AUTOSAR XML (schema 00050)
package /MICROSAR/Dem_swc/DataTypes
  23 x impl type:
    Dem_EventIdType: range raw 1..65535, implementation-data-type=uint16
    Dem_RatioIdType: range raw 1..65535, implementation-data-type=uint16
    Dem_DTCStatusMaskType: range raw 0..255, implementation-data-type=uint8
    Dem_OperationCycleIdType: range raw 0..255, implementation-data-type=uint8
    Dem_DTCGroupType: range raw 0..16777215, implementation-data-type=uint32
    Dem_MaxDataValueType: category=ARRAY, sw-calibration-access=READ-ONLY
      element Dem_MaxDataValueTypeElement: array-size=1, array-size-semantics=FIXED-SIZE, implementation-data-type=uint8
    Dem_EventStatusType:
      compu {0=DEM_EVENT_STATUS_PASSED, 1=DEM_EVENT_STATUS_FAILED, 2=DEM_EVENT_STATUS_PREPASSED, 3=DEM_EVENT_STATUS_PREFAILED, 4=DEM_EVENT_STATUS_FDC_THRESHOLD_REACHED, 5=DEM_EVENT_STATUS_PASSED_CONDITIONS_NOT_FULFILLED, 6=DEM_EVENT_STATUS_FAILED_CONDITIONS_NOT_FULFILLED, 7=DEM_EVENT_STATUS_PREPASSED_CONDITIONS_NOT_FULFILLED, 8=DEM_EVENT_STATUS_PREFAILED_CONDITIONS_NOT_FULFILLED}
      range raw 0..255
      implementation-data-type=uint8
    Dem_InitMonitorReasonType: compu {1=DEM_INIT_MONITOR_CLEAR, 2=DEM_INIT_MONITOR_RESTART, 3=DEM_INIT_MONITOR_REENABLED, 4=DEM_INIT_MONITOR_STORAGE_REENABLED}, range raw 1..4, implementation-data-type=uint8
    Dem_DTCOriginType: compu {1=DEM_DTC_ORIGIN_PRIMARY_MEMORY, 2=DEM_DTC_ORIGIN_MIRROR_MEMORY, 3=DEM_DTC_ORIGIN_PERMANENT_MEMORY, 4=DEM_DTC_ORIGIN_OBD_RELEVANT_MEMORY, 256=DEM_DTC_ORIGIN_SECONDARY_MEMORY}, range raw 1..511, implementation-data-type=uint16
    Dem_DTCFormatType: compu {0=DEM_DTC_FORMAT_OBD, 1=DEM_DTC_FORMAT_UDS, 2=DEM_DTC_FORMAT_J1939}, range raw 0..2, implementation-data-type=uint8
    Dem_OperationCycleStateType: compu {0=DEM_CYCLE_STATE_START, 1=DEM_CYCLE_STATE_END}, range raw 0..1, implementation-data-type=uint8
    Dem_IndicatorStatusType: compu {0=DEM_INDICATOR_OFF, 1=DEM_INDICATOR_CONTINUOUS, 2=DEM_INDICATOR_BLINKING, 3=DEM_INDICATOR_BLINK_CONT, 4=DEM_INDICATOR_SLOW_FLASH, 5=DEM_INDICATOR_FAST_FLASH, 6=DEM_INDICATOR_ON_DEMAND, 7=DEM_INDICATOR_SHORT}, range raw 0..7, implementation-data-type=uint8
    Dem_DTCKindType: compu {1=DEM_DTC_KIND_ALL_DTCS, 2=DEM_DTC_KIND_EMISSION_REL_DTCS}, range raw 0..255, implementation-data-type=uint8
    Dem_IumprDenomCondIdType: compu {1=DEM_IUMPR_GENERAL_DENOMINATOR, 2=DEM_IUMPR_DEN_COND_COLDSTART, 3=DEM_IUMPR_DEN_COND_EVAP, 4=DEM_IUMPR_DEN_COND_500MI, 5=DEM_IUMPR_GENERAL_INDIVIDUAL_DENOMINATOR, 6=DEM_IUMPR_GENERAL_OBDCOND, 7=DEM_IUMPR_DEN_COND_INDEPENDENT}, range raw 0..255, implementation-data-type=uint8
    Dem_IumprDenomCondStatusType: compu {0=DEM_IUMPR_DEN_STATUS_NOT_REACHED, 1=DEM_IUMPR_DEN_STATUS_REACHED, 2=DEM_IUMPR_DEN_STATUS_INHIBITED}, range raw 0..255, implementation-data-type=uint8
    Dem_DebounceResetStatusType: compu {0=DEM_DEBOUNCE_STATUS_FREEZE, 1=DEM_DEBOUNCE_STATUS_RESET}, range raw 0..255, implementation-data-type=uint8
    Dem_IumprReadinessGroupType:
      compu {0=DEM_IUMPR_BOOSTPRS, 1=DEM_IUMPR_CAT1, 2=DEM_IUMPR_CAT2, 3=DEM_IUMPR_EGR, 4=DEM_IUMPR_EGSENSOR, 5=DEM_IUMPR_EVAP, 6=DEM_IUMPR_NMHCCAT, 7=DEM_IUMPR_NOXADSORB, 8=DEM_IUMPR_NOXCAT, 9=DEM_IUMPR_OXS1, 10=DEM_IUMPR_OXS2, 11=DEM_IUMPR_PMFILTER, 12=DEM_IUMPR_PRIVATE, 13=DEM_IUMPR_SAIR, 14=DEM_IUMPR_SECOXS1, 15=DEM_IUMPR_SECOXS2, 16=DEM_IUMPR_FLSYS, 17=DEM_IUMPR_AFRI1, 18=DEM_IUMPR_AFRI2, 19=DEM_IUMPR_PF1, 20=DEM_IUMPR_PF2, 255=DEM_IUMPR_ALLGROUPS}
      range raw 0..255
      implementation-data-type=uint8
    Dem_DTRControlType: compu {0=DEM_DTR_CTL_NORMAL, 1=DEM_DTR_CTL_NO_MAX, 2=DEM_DTR_CTL_NO_MIN, 3=DEM_DTR_CTL_RESET, 4=DEM_DTR_CTL_INVISIBLE}, range raw 0..255, implementation-data-type=uint8
    Dem_DebouncingStateType:
      compu {mask 1: 1=DEM_TEMPORARILY_DEFECTIVE (Bit 0: Temporarily Defective (corresponds to 0 < FDC < 127)), mask 2: 2=DEM_FINALLY_DEFECTIVE (Bit 1: Finally Defective (corresponds to FDC = 127)), mask 4: 4=DEM_TEMPORARILY_HEALED (Bit 2: Temporarily healed (corresponds to -128 < FDC < 0)), mask 8: 8=DEM_TEST_COMPLETE (Bit 3: Test complete (corresponds to FDC = -128 or FDC = 127)), mask 16: 16=DEM_DTR_UPDATE (Bit 4: DTR Update (= Test complete && Debouncing complete && enable conditions / storage conditions fulfilled))}
      range raw 0..255
      implementation-data-type=uint8
    Dem_DTCSeverityType:
      compu {mask 255: 0=DEM_SEVERITY_NO_SEVERITY (DTC_NO_SEVERITY) (No severity information available), mask 31: 1=DEM_SEVERITY_WWHOBD_CLASS_NO_CLASS (DTC_CLASS) (No class information), mask 31: 2=DEM_SEVERITY_WWHOBD_CLASS_A (DTC_CLASS) (WWH-OBD Class A), mask 31: 4=DEM_SEVERITY_WWHOBD_CLASS_B1 (DTC_CLASS) (WWH-OBD Class B1), mask 31: 8=DEM_SEVERITY_WWHOBD_CLASS_B2 (DTC_CLASS) (WWH-OBD Class B2), mask 31: 16=DEM_SEVERITY_WWHOBD_CLASS_C (DTC_CLASS) (WWH-OBD Class C), mask 224: 32=DEM_SEVERITY_MAINTENANCE_ONLY (DTC_SEVERITY) (Maintenance required), mask 224: 64=DEM_SEVERITY_CHECK_AT_NEXT_HALT (DTC_SEVERITY) (Check at next halt), mask 224: 128=DEM_SEVERITY_CHECK_IMMEDIATELY (DTC_SEVERITY) (Check immediately)}
      range raw 0..255
      implementation-data-type=uint8
    Dem_UdsStatusByteType:
      compu {mask 1: 1=DEM_UDS_STATUS_TF (bit 0: TestFailed), mask 2: 2=DEM_UDS_STATUS_TFTOC (bit 1: TestFailedThisOperationCycle), mask 4: 4=DEM_UDS_STATUS_PDTC (bit 2: PendingDTC), mask 8: 8=DEM_UDS_STATUS_CDTC (bit 3: ConfirmedDTC), mask 16: 16=DEM_UDS_STATUS_TNCSLC (bit 4: TestNotCompletedSinceLastClear), mask 32: 32=DEM_UDS_STATUS_TFSLC (bit 5: TestFailedSinceLastClear), mask 64: 64=DEM_UDS_STATUS_TNCTOC (bit 6: TestNotCompletedThisOperationCycle), mask 128: 128=DEM_UDS_STATUS_WIR (bit 7: WarningIndicatorRequested)}
      range raw 0..255
      implementation-data-type=uint8
    Dem_MonitorStatusType: compu {mask 1: 1=DEM_MONITOR_STATUS_TF (bit 0: TestFailed), mask 2: 2=DEM_MONITOR_STATUS_TNCTOC (bit 1: TestNotCompletedThisOperationCycle)}, range raw 0..255, implementation-data-type=uint8
    DataPrimitiveType_uint8: implementation-data-type=uint8
package /MICROSAR/Dem_swc/Interfaces
  9 x client server interface, all with is-service=true, service-kind=DIAGNOSTIC-EVENT-MANAGER:
    DemServices
      operation GetPostRunRequested: possible-error=DemServices/E_NOT_OK
        arg IsRequested: type=boolean, direction=OUT
      operation GetDTCStatusAvailabilityMask: possible-error=DemServices/E_NOT_OK
        arg ClientId: type=uint8, direction=IN
        arg DTCStatusMask: type=uint8, direction=OUT
      error E_NOT_OK: error-code=1
    ClearDTC
      operation ClearDTC: possible-error=[ClearDTC/E_NOT_OK, DEM_CLEAR_FAILED, DEM_PENDING, DEM_CLEAR_BUSY, DEM_CLEAR_MEMORY_ERROR, DEM_WRONG_DTC, DEM_WRONG_DTCORIGIN]
      operation SelectDTC: possible-error=[ClearDTC/E_OK, ClearDTC/E_NOT_OK]
        arg DTC: type=uint32, direction=IN
        arg DTCFormat: type=Dem_DTCFormatType, direction=IN
        arg DTCOrigin: type=Dem_DTCOriginType, direction=IN
      8 x error:
        E_OK: error-code=0
        E_NOT_OK: error-code=1
        DEM_CLEAR_FAILED: error-code=7
        DEM_PENDING: error-code=4
        DEM_CLEAR_BUSY: error-code=5
        DEM_CLEAR_MEMORY_ERROR: error-code=6
        DEM_WRONG_DTC: error-code=8
        DEM_WRONG_DTCORIGIN: error-code=9
    EvMemOverflowIndication
      operation GetEventMemoryOverflow: possible-error=EvMemOverflowIndication/E_NOT_OK
        arg OverflowIndication: type=boolean, direction=OUT
      operation GetNumberOfEventMemoryEntries: possible-error=EvMemOverflowIndication/E_NOT_OK
        arg NumberOfEventMemoryEntries: type=uint8, direction=OUT
      error E_NOT_OK: error-code=1
    GeneralDiagnosticInfo
      11 x operation:
        GetEventUdsStatus: possible-error=GeneralDiagnosticInfo/E_NOT_OK
          arg EventId: type=Dem_EventIdType, direction=IN
          arg UDSStatusByte: type=Dem_UdsStatusByteType, direction=OUT
        GetEventStatus: possible-error=GeneralDiagnosticInfo/E_NOT_OK
          arg EventId: type=Dem_EventIdType, direction=IN
          arg UDSStatusByte: type=Dem_UdsStatusByteType, direction=OUT
        GetEventFailed: possible-error=GeneralDiagnosticInfo/E_NOT_OK
          arg EventId: type=Dem_EventIdType, direction=IN
          arg EventFailed: type=boolean, direction=OUT
        GetEventTested: possible-error=GeneralDiagnosticInfo/E_NOT_OK
          arg EventId: type=Dem_EventIdType, direction=IN
          arg EventTested: type=boolean, direction=OUT
        GetDTCOfEvent: possible-error=[GeneralDiagnosticInfo/E_NOT_OK, GeneralDiagnosticInfo/DEM_E_NO_DTC_AVAILABLE]
          arg EventId: type=Dem_EventIdType, direction=IN
          arg DTCFormat: type=Dem_DTCFormatType, direction=IN
          arg DTCOfEvent: type=uint32, direction=OUT
        GetFaultDetectionCounter: possible-error=[GeneralDiagnosticInfo/E_NOT_OK, GeneralDiagnosticInfo/DEM_E_NO_FDC_AVAILABLE]
          arg EventId: type=Dem_EventIdType, direction=IN
          arg FaultDetectionCounter: type=sint8, direction=OUT
        GetEventFreezeFrameDataEx: possible-error=[GeneralDiagnosticInfo/E_NOT_OK, GeneralDiagnosticInfo/DEM_BUFFER_TOO_SMALL, GeneralDiagnosticInfo/DEM_NO_SUCH_ELEMENT]
          5 x arg:
            EventId: type=Dem_EventIdType, direction=IN
            RecordNumber: type=uint8, direction=IN
            DataId: type=uint16, direction=IN
            DestBuffer: type=Dem_MaxDataValueType, direction=OUT
            BufSize: type=uint16, direction=INOUT
        GetEventExtendedDataRecordEx: possible-error=[GeneralDiagnosticInfo/E_NOT_OK, GeneralDiagnosticInfo/DEM_BUFFER_TOO_SMALL, GeneralDiagnosticInfo/DEM_NO_SUCH_ELEMENT]
          4 x arg:
            EventId: type=Dem_EventIdType, direction=IN
            RecordNumber: type=uint8, direction=IN
            DestBuffer: type=Dem_MaxDataValueType, direction=OUT
            BufSize: type=uint16, direction=INOUT
        GetEventEnableCondition: possible-error=GeneralDiagnosticInfo/E_NOT_OK
          arg EventId: type=Dem_EventIdType, direction=IN
          arg ConditionFullfilled: type=boolean, direction=OUT
        GetDebouncingOfEvent: possible-error=GeneralDiagnosticInfo/E_NOT_OK
          arg EventId: type=Dem_EventIdType, direction=IN
          arg DebouncingState: type=Dem_DebouncingStateType, direction=OUT
        GetMonitorStatus: possible-error=GeneralDiagnosticInfo/E_NOT_OK
          arg EventId: type=Dem_EventIdType, direction=IN
          arg MonitorStatus: type=Dem_MonitorStatusType, direction=OUT
      5 x error:
        E_NOT_OK: error-code=1
        DEM_E_NO_DTC_AVAILABLE: error-code=10
        DEM_E_NO_FDC_AVAILABLE: error-code=14
        DEM_BUFFER_TOO_SMALL: error-code=21
        DEM_NO_SUCH_ELEMENT: error-code=48
    OperationCycle
      operation GetOperationCycleState: possible-error=[OperationCycle/E_OK, OperationCycle/E_NOT_OK]
        arg CycleState: type=Dem_OperationCycleStateType, direction=OUT
      operation SetOperationCycleState: possible-error=[OperationCycle/E_OK, OperationCycle/E_NOT_OK]
        arg CycleState: type=Dem_OperationCycleStateType, direction=IN
      error E_OK: error-code=0
      error E_NOT_OK: error-code=1
    CSDataServices_DID_0x2_Current
      operation ReadData: possible-error=CSDataServices_DID_0x2_Current/E_NOT_OK
        arg Data: type=DataPrimitiveType_uint8, direction=OUT
      error E_NOT_OK: error-code=1
    DiagnosticInfo
      11 x operation:
        GetEventUdsStatus: possible-error=DiagnosticInfo/E_NOT_OK
          arg UDSStatusByte: type=Dem_UdsStatusByteType, direction=OUT
        GetEventStatus: possible-error=DiagnosticInfo/E_NOT_OK
          arg UDSStatusByte: type=Dem_UdsStatusByteType, direction=OUT
        GetEventFailed: possible-error=DiagnosticInfo/E_NOT_OK
          arg EventFailed: type=boolean, direction=OUT
        GetEventTested: possible-error=DiagnosticInfo/E_NOT_OK
          arg EventTested: type=boolean, direction=OUT
        GetDTCOfEvent: possible-error=[DiagnosticInfo/E_NOT_OK, DiagnosticInfo/DEM_E_NO_DTC_AVAILABLE]
          arg DTCFormat: type=Dem_DTCFormatType, direction=IN
          arg DTCOfEvent: type=uint32, direction=OUT
        GetFaultDetectionCounter: possible-error=[DiagnosticInfo/E_NOT_OK, DiagnosticInfo/DEM_E_NO_FDC_AVAILABLE]
          arg FaultDetectionCounter: type=sint8, direction=OUT
        GetEventFreezeFrameDataEx: possible-error=[DiagnosticInfo/E_NOT_OK, DiagnosticInfo/DEM_BUFFER_TOO_SMALL, DiagnosticInfo/DEM_NO_SUCH_ELEMENT]
          4 x arg:
            RecordNumber: type=uint8, direction=IN
            DataId: type=uint16, direction=IN
            DestBuffer: type=Dem_MaxDataValueType, direction=OUT
            BufSize: type=uint16, direction=INOUT
        GetEventExtendedDataRecordEx: possible-error=[DiagnosticInfo/E_NOT_OK, DiagnosticInfo/DEM_BUFFER_TOO_SMALL, DiagnosticInfo/DEM_NO_SUCH_ELEMENT]
          arg RecordNumber: type=uint8, direction=IN
          arg DestBuffer: type=Dem_MaxDataValueType, direction=OUT
          arg BufSize: type=uint16, direction=INOUT
        GetEventEnableCondition: possible-error=DiagnosticInfo/E_NOT_OK
          arg ConditionFullfilled: type=boolean, direction=OUT
        GetDebouncingOfEvent: possible-error=DiagnosticInfo/E_NOT_OK
          arg DebouncingState: type=Dem_DebouncingStateType, direction=OUT
        GetMonitorStatus: possible-error=DiagnosticInfo/E_NOT_OK
          arg MonitorStatus: type=Dem_MonitorStatusType, direction=OUT
      5 x error:
        E_NOT_OK: error-code=1
        DEM_E_NO_DTC_AVAILABLE: error-code=10
        DEM_E_NO_FDC_AVAILABLE: error-code=14
        DEM_BUFFER_TOO_SMALL: error-code=21
        DEM_NO_SUCH_ELEMENT: error-code=48
    DiagnosticMonitor
      11 x operation:
        SetEventStatus: possible-error=DiagnosticMonitor/E_NOT_OK
          arg EventStatus: type=Dem_EventStatusType, direction=IN
        ResetEventStatus: possible-error=DiagnosticMonitor/E_NOT_OK
        ResetEventDebounceStatus: possible-error=DiagnosticMonitor/E_NOT_OK
          arg DebounceResetStatus: type=Dem_DebounceResetStatusType, direction=IN
        GetEventUdsStatus: possible-error=DiagnosticMonitor/E_NOT_OK
          arg UDSStatusByte: type=Dem_UdsStatusByteType, direction=OUT
        GetEventStatus: possible-error=DiagnosticMonitor/E_NOT_OK
          arg UDSStatusByte: type=Dem_UdsStatusByteType, direction=OUT
        GetEventFailed: possible-error=DiagnosticMonitor/E_NOT_OK
          arg EventFailed: type=boolean, direction=OUT
        GetEventTested: possible-error=DiagnosticMonitor/E_NOT_OK
          arg EventTested: type=boolean, direction=OUT
        GetDTCOfEvent: possible-error=[DiagnosticMonitor/E_NOT_OK, DiagnosticMonitor/DEM_E_NO_DTC_AVAILABLE]
          arg DTCFormat: type=Dem_DTCFormatType, direction=IN
          arg DTCOfEvent: type=uint32, direction=OUT
        GetFaultDetectionCounter: possible-error=[DiagnosticMonitor/E_NOT_OK, DiagnosticMonitor/DEM_E_NO_FDC_AVAILABLE]
          arg FaultDetectionCounter: type=sint8, direction=OUT
        GetEventFreezeFrameDataEx: possible-error=[DiagnosticMonitor/E_NOT_OK, DiagnosticMonitor/DEM_BUFFER_TOO_SMALL, DiagnosticMonitor/DEM_NO_SUCH_ELEMENT]
          4 x arg:
            RecordNumber: type=uint8, direction=IN
            DataId: type=uint16, direction=IN
            DestBuffer: type=Dem_MaxDataValueType, direction=OUT
            BufSize: type=uint16, direction=INOUT
        GetEventExtendedDataRecordEx: possible-error=[DiagnosticMonitor/E_NOT_OK, DiagnosticMonitor/DEM_BUFFER_TOO_SMALL, DiagnosticMonitor/DEM_NO_SUCH_ELEMENT]
          arg RecordNumber: type=uint8, direction=IN
          arg DestBuffer: type=Dem_MaxDataValueType, direction=OUT
          arg BufSize: type=uint16, direction=INOUT
      5 x error:
        E_NOT_OK: error-code=1
        DEM_E_NO_DTC_AVAILABLE: error-code=10
        DEM_E_NO_FDC_AVAILABLE: error-code=14
        DEM_BUFFER_TOO_SMALL: error-code=21
        DEM_NO_SUCH_ELEMENT: error-code=48
    CallbackGetFaultDetectCounter
      operation GetFaultDetectionCounter: possible-error=CallbackGetFaultDetectCounter/E_NOT_OK
        arg FaultDetectionCounter: type=sint8, direction=OUT
      error E_NOT_OK: error-code=1
package /MICROSAR/Dem_swc/ComponentTypes
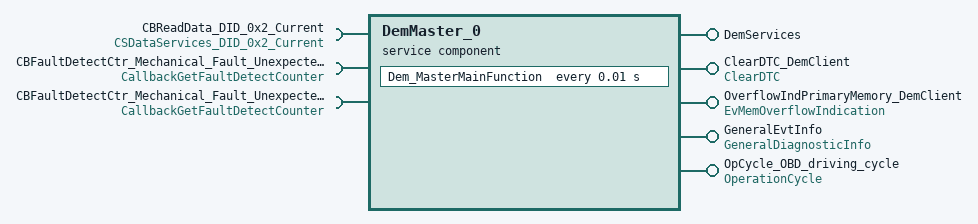
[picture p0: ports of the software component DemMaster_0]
  service sw component type DemMaster_0: category=SERVICE_COMPONENT
    5 x provide port:
      DemServices: provided-interface=DemServices
      ClearDTC_DemClient: provided-interface=ClearDTC
      OverflowIndPrimaryMemory_DemClient: provided-interface=EvMemOverflowIndication
      GeneralEvtInfo: provided-interface=GeneralDiagnosticInfo
      OpCycle_OBD_driving_cycle: provided-interface=OperationCycle
    require port CBReadData_DID_0x2_Current: required-interface=CSDataServices_DID_0x2_Current
    require port CBFaultDetectCtr_Mechanical_Fault_Unexpected_High_Current: required-interface=CallbackGetFaultDetectCounter
    require port CBFaultDetectCtr_Mechanical_Fault_Unexpected_Low_Current: required-interface=CallbackGetFaultDetectCounter
    behavior DemMaster_0InternalBehavior: handle-termination-and-restart=NO-SUPPORT, included-data-type-set=data-type=[Dem_EventIdType, Dem_RatioIdType, Dem_EventStatusType, Dem_UdsStatusByteType, Dem_DTCFormatType, Dem_InitMonitorReasonType, Dem_OperationCycleStateType, Dem_DTCStatusMaskType, Dem_IndicatorStatusType, Dem_MaxDataValueType, Dem_DTCKindType, Dem_DTCGroupType, Dem_IumprDenomCondIdType, Dem_IumprDenomCondStatusType, Dem_DebounceResetStatusType, Dem_DebouncingStateType, Dem_IumprReadinessGroupType, Dem_DTRControlType, Dem_DTCSeverityType, Dem_MonitorStatusType]
      timing event Timer_Dem_MasterMainFunction: start-on-event=Dem_MasterMainFunction, period=0.01
      19 x operation invoked event:
        OpEventPostRunRequested_GetPostRunRequested_DemServices: start-on-event=PostRunRequested, operation=DemServices.GetPostRunRequested
        OpEventGetDTCStatusAvailabilityMask_GetDTCStatusAvailabilityMask_DemServices: start-on-event=GetDTCStatusAvailabilityMask, operation=DemServices.GetDTCStatusAvailabilityMask
        OpEventClearDTC_ClearDTC_ClearDTC_DemClient: start-on-event=ClearDTC, operation=ClearDTC_DemClient.ClearDTC
        OpEventSelectDTC_SelectDTC_ClearDTC_DemClient: start-on-event=SelectDTC, operation=ClearDTC_DemClient.SelectDTC
        OpEventGetEventMemoryOverflow_GetEventMemoryOverflow_OverflowIndPrimaryMemory_DemClient: start-on-event=GetEventMemoryOverflow, operation=OverflowIndPrimaryMemory_DemClient.GetEventMemoryOverflow
        OpEventGetNumberOfEventMemoryEntries_GetNumberOfEventMemoryEntries_OverflowIndPrimaryMemory_DemClient: start-on-event=GetNumberOfEventMemoryEntries, operation=OverflowIndPrimaryMemory_DemClient.GetNumberOfEventMemoryEntries
        OpEventGetEventUdsStatus_GetEventUdsStatus_GeneralEvtInfo: start-on-event=DemMaster_0InternalBehavior/GetEventUdsStatus, operation=GeneralEvtInfo.GetEventUdsStatus
        OpEventGetEventStatus_GetEventStatus_GeneralEvtInfo: start-on-event=DemMaster_0InternalBehavior/GetEventStatus, operation=GeneralEvtInfo.GetEventStatus
        OpEventGetEventFailed_GetEventFailed_GeneralEvtInfo: start-on-event=DemMaster_0InternalBehavior/GetEventFailed, operation=GeneralEvtInfo.GetEventFailed
        OpEventGetEventTested_GetEventTested_GeneralEvtInfo: start-on-event=DemMaster_0InternalBehavior/GetEventTested, operation=GeneralEvtInfo.GetEventTested
        OpEventGetDTCOfEvent_GetDTCOfEvent_GeneralEvtInfo: start-on-event=DemMaster_0InternalBehavior/GetDTCOfEvent, operation=GeneralEvtInfo.GetDTCOfEvent
        OpEventGetFaultDetectionCounter_GetFaultDetectionCounter_GeneralEvtInfo: start-on-event=DemMaster_0InternalBehavior/GetFaultDetectionCounter, operation=GeneralEvtInfo.GetFaultDetectionCounter
        OpEventGetEventFreezeFrameDataEx_GetEventFreezeFrameDataEx_GeneralEvtInfo: start-on-event=DemMaster_0InternalBehavior/GetEventFreezeFrameDataEx, operation=GeneralEvtInfo.GetEventFreezeFrameDataEx
        OpEventGetEventExtendedDataRecordEx_GetEventExtendedDataRecordEx_GeneralEvtInfo: start-on-event=DemMaster_0InternalBehavior/GetEventExtendedDataRecordEx, operation=GeneralEvtInfo.GetEventExtendedDataRecordEx
        OpEventGetEventEnableCondition_GetEventEnableCondition_GeneralEvtInfo: start-on-event=DemMaster_0InternalBehavior/GetEventEnableCondition, operation=GeneralEvtInfo.GetEventEnableCondition
        OpEventGetDebouncingOfEvent_GetDebouncingOfEvent_GeneralEvtInfo: start-on-event=DemMaster_0InternalBehavior/GetDebouncingOfEvent, operation=GeneralEvtInfo.GetDebouncingOfEvent
        OpEventGetMonitorStatus_GetMonitorStatus_GeneralEvtInfo: start-on-event=DemMaster_0InternalBehavior/GetMonitorStatus, operation=GeneralEvtInfo.GetMonitorStatus
        OpEventGetOperationCycleState_GetOperationCycleState_OpCycle_OBD_driving_cycle: start-on-event=GetOperationCycleState, operation=OpCycle_OBD_driving_cycle.GetOperationCycleState
        OpEventSetOperationCycleState_SetOperationCycleState_OpCycle_OBD_driving_cycle: start-on-event=SetOperationCycleState, operation=OpCycle_OBD_driving_cycle.SetOperationCycleState
      port-api-options:
        enable-take-address=true, indirect-api=false, port=DemServices
        {enable-take-address=true, indirect-api=false, port-defined-argument-value{value=0, value-type=uint8}, port=ClearDTC_DemClient}
        {enable-take-address=true, indirect-api=false, port-arg-values=[{value=0, value-type=uint8}, {value=1, value-type=Dem_DTCOriginType}], port=OverflowIndPrimaryMemory_DemClient}
        enable-take-address=true, indirect-api=false, port=DemMaster_0/GeneralEvtInfo
        enable-take-address=true, indirect-api=false, port=DemMaster_0/CBReadData_DID_0x2_Current
        {enable-take-address=true, indirect-api=false, port-defined-argument-value{value=0, value-type=uint8}, port=OpCycle_OBD_driving_cycle}
        enable-take-address=true, indirect-api=false, port=CBFaultDetectCtr_Mechanical_Fault_Unexpected_High_Current
        enable-take-address=true, indirect-api=false, port=CBFaultDetectCtr_Mechanical_Fault_Unexpected_Low_Current
      20 x runnable:
        Dem_MasterMainFunction
          sync call OpServerCallDem_MasterMainFunction_ReadData_CBReadData_DID_0x2_Current: operation=CBReadData_DID_0x2_Current.ReadData, timeout=0
          sync call OpServerCallDem_MasterMainFunction_GetFaultDetectionCounter_CBFaultDetectCtr_Mechanical_Fault_Unexpected_High_Current: operation=CBFaultDetectCtr_Mechanical_Fault_Unexpected_High_Current.GetFaultDetectionCounter, timeout=0
          sync call OpServerCallDem_MasterMainFunction_GetFaultDetectionCounter_CBFaultDetectCtr_Mechanical_Fault_Unexpected_Low_Current: operation=CBFaultDetectCtr_Mechanical_Fault_Unexpected_Low_Current.GetFaultDetectionCounter, timeout=0
        PostRunRequested: can-be-invoked-concurrently=true, symbol=Dem_PostRunRequested
        GetDTCStatusAvailabilityMask: can-be-invoked-concurrently=true, symbol=Dem_GetDTCStatusAvailabilityMask
        ClearDTC: can-be-invoked-concurrently=true, symbol=Dem_ClearDTC
        SelectDTC: can-be-invoked-concurrently=true, symbol=Dem_SelectDTC
        GetEventMemoryOverflow: can-be-invoked-concurrently=true, symbol=Dem_GetEventMemoryOverflow
        GetNumberOfEventMemoryEntries: can-be-invoked-concurrently=true, symbol=Dem_GetNumberOfEventMemoryEntries
        GetEventUdsStatus: can-be-invoked-concurrently=true, symbol=Dem_GetEventUdsStatus
        GetEventStatus: can-be-invoked-concurrently=true, symbol=Dem_GetEventUdsStatus
        GetEventFailed: can-be-invoked-concurrently=true, symbol=Dem_GetEventFailed
        GetEventTested: can-be-invoked-concurrently=true, symbol=Dem_GetEventTested
        GetDTCOfEvent: can-be-invoked-concurrently=true, symbol=Dem_GetDTCOfEvent
        GetFaultDetectionCounter: can-be-invoked-concurrently=true, symbol=Dem_GetFaultDetectionCounter
        GetEventFreezeFrameDataEx: can-be-invoked-concurrently=true, symbol=Dem_GetEventFreezeFrameDataEx
        GetEventExtendedDataRecordEx: can-be-invoked-concurrently=true, symbol=Dem_GetEventExtendedDataRecordEx
        GetEventEnableCondition: can-be-invoked-concurrently=true, symbol=Dem_GetEventEnableCondition
        GetDebouncingOfEvent: can-be-invoked-concurrently=true, symbol=Dem_GetDebouncingOfEvent
        GetMonitorStatus: can-be-invoked-concurrently=true, symbol=Dem_GetMonitorStatus
        GetOperationCycleState: can-be-invoked-concurrently=true, symbol=Dem_GetOperationCycleState
        SetOperationCycleState: can-be-invoked-concurrently=true, symbol=Dem_SetOperationCycleState
  swc implementation DemMaster_0Implementation: programming-language=C, behavior=DemMaster_0InternalBehavior
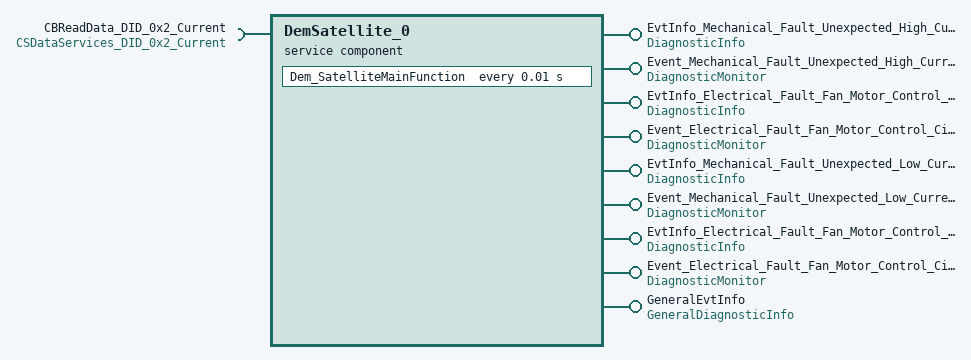
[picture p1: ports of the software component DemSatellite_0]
  service sw component type DemSatellite_0: category=SERVICE_COMPONENT
    9 x provide port:
      EvtInfo_Mechanical_Fault_Unexpected_High_Current: provided-interface=DiagnosticInfo
      Event_Mechanical_Fault_Unexpected_High_Current: provided-interface=DiagnosticMonitor
      EvtInfo_Electrical_Fault_Fan_Motor_Control_Circuit_Short: provided-interface=DiagnosticInfo
      Event_Electrical_Fault_Fan_Motor_Control_Circuit_Short: provided-interface=DiagnosticMonitor
      EvtInfo_Mechanical_Fault_Unexpected_Low_Current: provided-interface=DiagnosticInfo
      Event_Mechanical_Fault_Unexpected_Low_Current: provided-interface=DiagnosticMonitor
      EvtInfo_Electrical_Fault_Fan_Motor_Control_Circuit_Open: provided-interface=DiagnosticInfo
      Event_Electrical_Fault_Fan_Motor_Control_Circuit_Open: provided-interface=DiagnosticMonitor
      GeneralEvtInfo: provided-interface=GeneralDiagnosticInfo
    require port CBReadData_DID_0x2_Current: required-interface=CSDataServices_DID_0x2_Current
    behavior DemSatellite_0InternalBehavior: handle-termination-and-restart=NO-SUPPORT, included-data-type-set=data-type=[Dem_EventIdType, Dem_RatioIdType, Dem_EventStatusType, Dem_UdsStatusByteType, Dem_DTCFormatType, Dem_InitMonitorReasonType, Dem_OperationCycleStateType, Dem_DTCStatusMaskType, Dem_IndicatorStatusType, Dem_MaxDataValueType, Dem_DTCKindType, Dem_DTCGroupType, Dem_IumprDenomCondIdType, Dem_IumprDenomCondStatusType, Dem_DebounceResetStatusType, Dem_DebouncingStateType, Dem_IumprReadinessGroupType, Dem_DTRControlType, Dem_DTCSeverityType, Dem_MonitorStatusType]
      timing event Timer_Dem_SatelliteMainFunction: start-on-event=Dem_SatelliteMainFunction, period=0.01
      99 x operation invoked event:
        OpEventGetEventUdsStatus_GetEventUdsStatus_EvtInfo_Mechanical_Fault_Unexpected_High_Current: start-on-event=DemSatellite_0InternalBehavior/GetEventUdsStatus, operation=EvtInfo_Mechanical_Fault_Unexpected_High_Current.GetEventUdsStatus
        OpEventGetEventUdsStatus_GetEventUdsStatus_Event_Mechanical_Fault_Unexpected_High_Current: start-on-event=DemSatellite_0InternalBehavior/GetEventUdsStatus, operation=Event_Mechanical_Fault_Unexpected_High_Current.GetEventUdsStatus
        OpEventGetEventUdsStatus_GetEventUdsStatus_EvtInfo_Electrical_Fault_Fan_Motor_Control_Circuit_Short: start-on-event=DemSatellite_0InternalBehavior/GetEventUdsStatus, operation=EvtInfo_Electrical_Fault_Fan_Motor_Control_Circuit_Short.GetEventUdsStatus
        OpEventGetEventUdsStatus_GetEventUdsStatus_Event_Electrical_Fault_Fan_Motor_Control_Circuit_Short: start-on-event=DemSatellite_0InternalBehavior/GetEventUdsStatus, operation=Event_Electrical_Fault_Fan_Motor_Control_Circuit_Short.GetEventUdsStatus
        OpEventGetEventUdsStatus_GetEventUdsStatus_EvtInfo_Mechanical_Fault_Unexpected_Low_Current: start-on-event=DemSatellite_0InternalBehavior/GetEventUdsStatus, operation=EvtInfo_Mechanical_Fault_Unexpected_Low_Current.GetEventUdsStatus
        OpEventGetEventUdsStatus_GetEventUdsStatus_Event_Mechanical_Fault_Unexpected_Low_Current: start-on-event=DemSatellite_0InternalBehavior/GetEventUdsStatus, operation=Event_Mechanical_Fault_Unexpected_Low_Current.GetEventUdsStatus
        OpEventGetEventUdsStatus_GetEventUdsStatus_EvtInfo_Electrical_Fault_Fan_Motor_Control_Circuit_Open: start-on-event=DemSatellite_0InternalBehavior/GetEventUdsStatus, operation=EvtInfo_Electrical_Fault_Fan_Motor_Control_Circuit_Open.GetEventUdsStatus
        OpEventGetEventUdsStatus_GetEventUdsStatus_Event_Electrical_Fault_Fan_Motor_Control_Circuit_Open: start-on-event=DemSatellite_0InternalBehavior/GetEventUdsStatus, operation=Event_Electrical_Fault_Fan_Motor_Control_Circuit_Open.GetEventUdsStatus
        OpEventGetEventUdsStatus_GetEventUdsStatus_GeneralEvtInfo: start-on-event=DemSatellite_0InternalBehavior/GetEventUdsStatus, operation=GeneralEvtInfo.GetEventUdsStatus
        OpEventGetEventStatus_GetEventStatus_EvtInfo_Mechanical_Fault_Unexpected_High_Current: start-on-event=DemSatellite_0InternalBehavior/GetEventStatus, operation=EvtInfo_Mechanical_Fault_Unexpected_High_Current.GetEventStatus
        OpEventGetEventStatus_GetEventStatus_Event_Mechanical_Fault_Unexpected_High_Current: start-on-event=DemSatellite_0InternalBehavior/GetEventStatus, operation=Event_Mechanical_Fault_Unexpected_High_Current.GetEventStatus
        OpEventGetEventStatus_GetEventStatus_EvtInfo_Electrical_Fault_Fan_Motor_Control_Circuit_Short: start-on-event=DemSatellite_0InternalBehavior/GetEventStatus, operation=EvtInfo_Electrical_Fault_Fan_Motor_Control_Circuit_Short.GetEventStatus
        OpEventGetEventStatus_GetEventStatus_Event_Electrical_Fault_Fan_Motor_Control_Circuit_Short: start-on-event=DemSatellite_0InternalBehavior/GetEventStatus, operation=Event_Electrical_Fault_Fan_Motor_Control_Circuit_Short.GetEventStatus
        OpEventGetEventStatus_GetEventStatus_EvtInfo_Mechanical_Fault_Unexpected_Low_Current: start-on-event=DemSatellite_0InternalBehavior/GetEventStatus, operation=EvtInfo_Mechanical_Fault_Unexpected_Low_Current.GetEventStatus
        OpEventGetEventStatus_GetEventStatus_Event_Mechanical_Fault_Unexpected_Low_Current: start-on-event=DemSatellite_0InternalBehavior/GetEventStatus, operation=Event_Mechanical_Fault_Unexpected_Low_Current.GetEventStatus
        OpEventGetEventStatus_GetEventStatus_EvtInfo_Electrical_Fault_Fan_Motor_Control_Circuit_Open: start-on-event=DemSatellite_0InternalBehavior/GetEventStatus, operation=EvtInfo_Electrical_Fault_Fan_Motor_Control_Circuit_Open.GetEventStatus
        OpEventGetEventStatus_GetEventStatus_Event_Electrical_Fault_Fan_Motor_Control_Circuit_Open: start-on-event=DemSatellite_0InternalBehavior/GetEventStatus, operation=Event_Electrical_Fault_Fan_Motor_Control_Circuit_Open.GetEventStatus
        OpEventGetEventStatus_GetEventStatus_GeneralEvtInfo: start-on-event=DemSatellite_0InternalBehavior/GetEventStatus, operation=GeneralEvtInfo.GetEventStatus
        OpEventGetEventFailed_GetEventFailed_EvtInfo_Mechanical_Fault_Unexpected_High_Current: start-on-event=DemSatellite_0InternalBehavior/GetEventFailed, operation=EvtInfo_Mechanical_Fault_Unexpected_High_Current.GetEventFailed
        OpEventGetEventFailed_GetEventFailed_Event_Mechanical_Fault_Unexpected_High_Current: start-on-event=DemSatellite_0InternalBehavior/GetEventFailed, operation=Event_Mechanical_Fault_Unexpected_High_Current.GetEventFailed
        OpEventGetEventFailed_GetEventFailed_EvtInfo_Electrical_Fault_Fan_Motor_Control_Circuit_Short: start-on-event=DemSatellite_0InternalBehavior/GetEventFailed, operation=EvtInfo_Electrical_Fault_Fan_Motor_Control_Circuit_Short.GetEventFailed
        OpEventGetEventFailed_GetEventFailed_Event_Electrical_Fault_Fan_Motor_Control_Circuit_Short: start-on-event=DemSatellite_0InternalBehavior/GetEventFailed, operation=Event_Electrical_Fault_Fan_Motor_Control_Circuit_Short.GetEventFailed
        OpEventGetEventFailed_GetEventFailed_EvtInfo_Mechanical_Fault_Unexpected_Low_Current: start-on-event=DemSatellite_0InternalBehavior/GetEventFailed, operation=EvtInfo_Mechanical_Fault_Unexpected_Low_Current.GetEventFailed
        OpEventGetEventFailed_GetEventFailed_Event_Mechanical_Fault_Unexpected_Low_Current: start-on-event=DemSatellite_0InternalBehavior/GetEventFailed, operation=Event_Mechanical_Fault_Unexpected_Low_Current.GetEventFailed
        OpEventGetEventFailed_GetEventFailed_EvtInfo_Electrical_Fault_Fan_Motor_Control_Circuit_Open: start-on-event=DemSatellite_0InternalBehavior/GetEventFailed, operation=EvtInfo_Electrical_Fault_Fan_Motor_Control_Circuit_Open.GetEventFailed
        OpEventGetEventFailed_GetEventFailed_Event_Electrical_Fault_Fan_Motor_Control_Circuit_Open: start-on-event=DemSatellite_0InternalBehavior/GetEventFailed, operation=Event_Electrical_Fault_Fan_Motor_Control_Circuit_Open.GetEventFailed
        OpEventGetEventFailed_GetEventFailed_GeneralEvtInfo: start-on-event=DemSatellite_0InternalBehavior/GetEventFailed, operation=GeneralEvtInfo.GetEventFailed
        OpEventGetEventTested_GetEventTested_EvtInfo_Mechanical_Fault_Unexpected_High_Current: start-on-event=DemSatellite_0InternalBehavior/GetEventTested, operation=EvtInfo_Mechanical_Fault_Unexpected_High_Current.GetEventTested
        OpEventGetEventTested_GetEventTested_Event_Mechanical_Fault_Unexpected_High_Current: start-on-event=DemSatellite_0InternalBehavior/GetEventTested, operation=Event_Mechanical_Fault_Unexpected_High_Current.GetEventTested
        OpEventGetEventTested_GetEventTested_EvtInfo_Electrical_Fault_Fan_Motor_Control_Circuit_Short: start-on-event=DemSatellite_0InternalBehavior/GetEventTested, operation=EvtInfo_Electrical_Fault_Fan_Motor_Control_Circuit_Short.GetEventTested
        OpEventGetEventTested_GetEventTested_Event_Electrical_Fault_Fan_Motor_Control_Circuit_Short: start-on-event=DemSatellite_0InternalBehavior/GetEventTested, operation=Event_Electrical_Fault_Fan_Motor_Control_Circuit_Short.GetEventTested
        OpEventGetEventTested_GetEventTested_EvtInfo_Mechanical_Fault_Unexpected_Low_Current: start-on-event=DemSatellite_0InternalBehavior/GetEventTested, operation=EvtInfo_Mechanical_Fault_Unexpected_Low_Current.GetEventTested
        OpEventGetEventTested_GetEventTested_Event_Mechanical_Fault_Unexpected_Low_Current: start-on-event=DemSatellite_0InternalBehavior/GetEventTested, operation=Event_Mechanical_Fault_Unexpected_Low_Current.GetEventTested
        OpEventGetEventTested_GetEventTested_EvtInfo_Electrical_Fault_Fan_Motor_Control_Circuit_Open: start-on-event=DemSatellite_0InternalBehavior/GetEventTested, operation=EvtInfo_Electrical_Fault_Fan_Motor_Control_Circuit_Open.GetEventTested
        OpEventGetEventTested_GetEventTested_Event_Electrical_Fault_Fan_Motor_Control_Circuit_Open: start-on-event=DemSatellite_0InternalBehavior/GetEventTested, operation=Event_Electrical_Fault_Fan_Motor_Control_Circuit_Open.GetEventTested
        OpEventGetEventTested_GetEventTested_GeneralEvtInfo: start-on-event=DemSatellite_0InternalBehavior/GetEventTested, operation=GeneralEvtInfo.GetEventTested
        OpEventGetDTCOfEvent_GetDTCOfEvent_EvtInfo_Mechanical_Fault_Unexpected_High_Current: start-on-event=DemSatellite_0InternalBehavior/GetDTCOfEvent, operation=EvtInfo_Mechanical_Fault_Unexpected_High_Current.GetDTCOfEvent
        OpEventGetDTCOfEvent_GetDTCOfEvent_Event_Mechanical_Fault_Unexpected_High_Current: start-on-event=DemSatellite_0InternalBehavior/GetDTCOfEvent, operation=Event_Mechanical_Fault_Unexpected_High_Current.GetDTCOfEvent
        OpEventGetDTCOfEvent_GetDTCOfEvent_EvtInfo_Electrical_Fault_Fan_Motor_Control_Circuit_Short: start-on-event=DemSatellite_0InternalBehavior/GetDTCOfEvent, operation=EvtInfo_Electrical_Fault_Fan_Motor_Control_Circuit_Short.GetDTCOfEvent
        OpEventGetDTCOfEvent_GetDTCOfEvent_Event_Electrical_Fault_Fan_Motor_Control_Circuit_Short: start-on-event=DemSatellite_0InternalBehavior/GetDTCOfEvent, operation=Event_Electrical_Fault_Fan_Motor_Control_Circuit_Short.GetDTCOfEvent
        OpEventGetDTCOfEvent_GetDTCOfEvent_EvtInfo_Mechanical_Fault_Unexpected_Low_Current: start-on-event=DemSatellite_0InternalBehavior/GetDTCOfEvent, operation=EvtInfo_Mechanical_Fault_Unexpected_Low_Current.GetDTCOfEvent
        OpEventGetDTCOfEvent_GetDTCOfEvent_Event_Mechanical_Fault_Unexpected_Low_Current: start-on-event=DemSatellite_0InternalBehavior/GetDTCOfEvent, operation=Event_Mechanical_Fault_Unexpected_Low_Current.GetDTCOfEvent
        OpEventGetDTCOfEvent_GetDTCOfEvent_EvtInfo_Electrical_Fault_Fan_Motor_Control_Circuit_Open: start-on-event=DemSatellite_0InternalBehavior/GetDTCOfEvent, operation=EvtInfo_Electrical_Fault_Fan_Motor_Control_Circuit_Open.GetDTCOfEvent
        OpEventGetDTCOfEvent_GetDTCOfEvent_Event_Electrical_Fault_Fan_Motor_Control_Circuit_Open: start-on-event=DemSatellite_0InternalBehavior/GetDTCOfEvent, operation=Event_Electrical_Fault_Fan_Motor_Control_Circuit_Open.GetDTCOfEvent
        OpEventGetDTCOfEvent_GetDTCOfEvent_GeneralEvtInfo: start-on-event=DemSatellite_0InternalBehavior/GetDTCOfEvent, operation=GeneralEvtInfo.GetDTCOfEvent
        OpEventGetFaultDetectionCounter_GetFaultDetectionCounter_EvtInfo_Mechanical_Fault_Unexpected_High_Current: start-on-event=DemSatellite_0InternalBehavior/GetFaultDetectionCounter, operation=EvtInfo_Mechanical_Fault_Unexpected_High_Current.GetFaultDetectionCounter
        OpEventGetFaultDetectionCounter_GetFaultDetectionCounter_Event_Mechanical_Fault_Unexpected_High_Current: start-on-event=DemSatellite_0InternalBehavior/GetFaultDetectionCounter, operation=Event_Mechanical_Fault_Unexpected_High_Current.GetFaultDetectionCounter
        OpEventGetFaultDetectionCounter_GetFaultDetectionCounter_EvtInfo_Electrical_Fault_Fan_Motor_Control_Circuit_Short: start-on-event=DemSatellite_0InternalBehavior/GetFaultDetectionCounter, operation=EvtInfo_Electrical_Fault_Fan_Motor_Control_Circuit_Short.GetFaultDetectionCounter
        OpEventGetFaultDetectionCounter_GetFaultDetectionCounter_Event_Electrical_Fault_Fan_Motor_Control_Circuit_Short: start-on-event=DemSatellite_0InternalBehavior/GetFaultDetectionCounter, operation=Event_Electrical_Fault_Fan_Motor_Control_Circuit_Short.GetFaultDetectionCounter
        OpEventGetFaultDetectionCounter_GetFaultDetectionCounter_EvtInfo_Mechanical_Fault_Unexpected_Low_Current: start-on-event=DemSatellite_0InternalBehavior/GetFaultDetectionCounter, operation=EvtInfo_Mechanical_Fault_Unexpected_Low_Current.GetFaultDetectionCounter
        OpEventGetFaultDetectionCounter_GetFaultDetectionCounter_Event_Mechanical_Fault_Unexpected_Low_Current: start-on-event=DemSatellite_0InternalBehavior/GetFaultDetectionCounter, operation=Event_Mechanical_Fault_Unexpected_Low_Current.GetFaultDetectionCounter
        OpEventGetFaultDetectionCounter_GetFaultDetectionCounter_EvtInfo_Electrical_Fault_Fan_Motor_Control_Circuit_Open: start-on-event=DemSatellite_0InternalBehavior/GetFaultDetectionCounter, operation=EvtInfo_Electrical_Fault_Fan_Motor_Control_Circuit_Open.GetFaultDetectionCounter
        OpEventGetFaultDetectionCounter_GetFaultDetectionCounter_Event_Electrical_Fault_Fan_Motor_Control_Circuit_Open: start-on-event=DemSatellite_0InternalBehavior/GetFaultDetectionCounter, operation=Event_Electrical_Fault_Fan_Motor_Control_Circuit_Open.GetFaultDetectionCounter
        OpEventGetFaultDetectionCounter_GetFaultDetectionCounter_GeneralEvtInfo: start-on-event=DemSatellite_0InternalBehavior/GetFaultDetectionCounter, operation=GeneralEvtInfo.GetFaultDetectionCounter
        OpEventGetEventFreezeFrameDataEx_GetEventFreezeFrameDataEx_EvtInfo_Mechanical_Fault_Unexpected_High_Current: start-on-event=DemSatellite_0InternalBehavior/GetEventFreezeFrameDataEx, operation=EvtInfo_Mechanical_Fault_Unexpected_High_Current.GetEventFreezeFrameDataEx
        OpEventGetEventFreezeFrameDataEx_GetEventFreezeFrameDataEx_Event_Mechanical_Fault_Unexpected_High_Current: start-on-event=DemSatellite_0InternalBehavior/GetEventFreezeFrameDataEx, operation=Event_Mechanical_Fault_Unexpected_High_Current.GetEventFreezeFrameDataEx
        OpEventGetEventFreezeFrameDataEx_GetEventFreezeFrameDataEx_EvtInfo_Electrical_Fault_Fan_Motor_Control_Circuit_Short: start-on-event=DemSatellite_0InternalBehavior/GetEventFreezeFrameDataEx, operation=EvtInfo_Electrical_Fault_Fan_Motor_Control_Circuit_Short.GetEventFreezeFrameDataEx
        OpEventGetEventFreezeFrameDataEx_GetEventFreezeFrameDataEx_Event_Electrical_Fault_Fan_Motor_Control_Circuit_Short: start-on-event=DemSatellite_0InternalBehavior/GetEventFreezeFrameDataEx, operation=Event_Electrical_Fault_Fan_Motor_Control_Circuit_Short.GetEventFreezeFrameDataEx
        OpEventGetEventFreezeFrameDataEx_GetEventFreezeFrameDataEx_EvtInfo_Mechanical_Fault_Unexpected_Low_Current: start-on-event=DemSatellite_0InternalBehavior/GetEventFreezeFrameDataEx, operation=EvtInfo_Mechanical_Fault_Unexpected_Low_Current.GetEventFreezeFrameDataEx
        OpEventGetEventFreezeFrameDataEx_GetEventFreezeFrameDataEx_Event_Mechanical_Fault_Unexpected_Low_Current: start-on-event=DemSatellite_0InternalBehavior/GetEventFreezeFrameDataEx, operation=Event_Mechanical_Fault_Unexpected_Low_Current.GetEventFreezeFrameDataEx
        OpEventGetEventFreezeFrameDataEx_GetEventFreezeFrameDataEx_EvtInfo_Electrical_Fault_Fan_Motor_Control_Circuit_Open: start-on-event=DemSatellite_0InternalBehavior/GetEventFreezeFrameDataEx, operation=EvtInfo_Electrical_Fault_Fan_Motor_Control_Circuit_Open.GetEventFreezeFrameDataEx
        OpEventGetEventFreezeFrameDataEx_GetEventFreezeFrameDataEx_Event_Electrical_Fault_Fan_Motor_Control_Circuit_Open: start-on-event=DemSatellite_0InternalBehavior/GetEventFreezeFrameDataEx, operation=Event_Electrical_Fault_Fan_Motor_Control_Circuit_Open.GetEventFreezeFrameDataEx
        OpEventGetEventFreezeFrameDataEx_GetEventFreezeFrameDataEx_GeneralEvtInfo: start-on-event=DemSatellite_0InternalBehavior/GetEventFreezeFrameDataEx, operation=GeneralEvtInfo.GetEventFreezeFrameDataEx
        OpEventGetEventExtendedDataRecordEx_GetEventExtendedDataRecordEx_EvtInfo_Mechanical_Fault_Unexpected_High_Current: start-on-event=DemSatellite_0InternalBehavior/GetEventExtendedDataRecordEx, operation=EvtInfo_Mechanical_Fault_Unexpected_High_Current.GetEventExtendedDataRecordEx
        OpEventGetEventExtendedDataRecordEx_GetEventExtendedDataRecordEx_Event_Mechanical_Fault_Unexpected_High_Current: start-on-event=DemSatellite_0InternalBehavior/GetEventExtendedDataRecordEx, operation=Event_Mechanical_Fault_Unexpected_High_Current.GetEventExtendedDataRecordEx
        OpEventGetEventExtendedDataRecordEx_GetEventExtendedDataRecordEx_EvtInfo_Electrical_Fault_Fan_Motor_Control_Circuit_Short: start-on-event=DemSatellite_0InternalBehavior/GetEventExtendedDataRecordEx, operation=EvtInfo_Electrical_Fault_Fan_Motor_Control_Circuit_Short.GetEventExtendedDataRecordEx
        OpEventGetEventExtendedDataRecordEx_GetEventExtendedDataRecordEx_Event_Electrical_Fault_Fan_Motor_Control_Circuit_Short: start-on-event=DemSatellite_0InternalBehavior/GetEventExtendedDataRecordEx, operation=Event_Electrical_Fault_Fan_Motor_Control_Circuit_Short.GetEventExtendedDataRecordEx
        OpEventGetEventExtendedDataRecordEx_GetEventExtendedDataRecordEx_EvtInfo_Mechanical_Fault_Unexpected_Low_Current: start-on-event=DemSatellite_0InternalBehavior/GetEventExtendedDataRecordEx, operation=EvtInfo_Mechanical_Fault_Unexpected_Low_Current.GetEventExtendedDataRecordEx
        OpEventGetEventExtendedDataRecordEx_GetEventExtendedDataRecordEx_Event_Mechanical_Fault_Unexpected_Low_Current: start-on-event=DemSatellite_0InternalBehavior/GetEventExtendedDataRecordEx, operation=Event_Mechanical_Fault_Unexpected_Low_Current.GetEventExtendedDataRecordEx
        OpEventGetEventExtendedDataRecordEx_GetEventExtendedDataRecordEx_EvtInfo_Electrical_Fault_Fan_Motor_Control_Circuit_Open: start-on-event=DemSatellite_0InternalBehavior/GetEventExtendedDataRecordEx, operation=EvtInfo_Electrical_Fault_Fan_Motor_Control_Circuit_Open.GetEventExtendedDataRecordEx
        OpEventGetEventExtendedDataRecordEx_GetEventExtendedDataRecordEx_Event_Electrical_Fault_Fan_Motor_Control_Circuit_Open: start-on-event=DemSatellite_0InternalBehavior/GetEventExtendedDataRecordEx, operation=Event_Electrical_Fault_Fan_Motor_Control_Circuit_Open.GetEventExtendedDataRecordEx
        OpEventGetEventExtendedDataRecordEx_GetEventExtendedDataRecordEx_GeneralEvtInfo: start-on-event=DemSatellite_0InternalBehavior/GetEventExtendedDataRecordEx, operation=GeneralEvtInfo.GetEventExtendedDataRecordEx
        OpEventGetEventEnableCondition_GetEventEnableCondition_EvtInfo_Mechanical_Fault_Unexpected_High_Current: start-on-event=DemSatellite_0InternalBehavior/GetEventEnableCondition, operation=EvtInfo_Mechanical_Fault_Unexpected_High_Current.GetEventEnableCondition
        OpEventGetEventEnableCondition_GetEventEnableCondition_EvtInfo_Electrical_Fault_Fan_Motor_Control_Circuit_Short: start-on-event=DemSatellite_0InternalBehavior/GetEventEnableCondition, operation=EvtInfo_Electrical_Fault_Fan_Motor_Control_Circuit_Short.GetEventEnableCondition
        OpEventGetEventEnableCondition_GetEventEnableCondition_EvtInfo_Mechanical_Fault_Unexpected_Low_Current: start-on-event=DemSatellite_0InternalBehavior/GetEventEnableCondition, operation=EvtInfo_Mechanical_Fault_Unexpected_Low_Current.GetEventEnableCondition
        OpEventGetEventEnableCondition_GetEventEnableCondition_EvtInfo_Electrical_Fault_Fan_Motor_Control_Circuit_Open: start-on-event=DemSatellite_0InternalBehavior/GetEventEnableCondition, operation=EvtInfo_Electrical_Fault_Fan_Motor_Control_Circuit_Open.GetEventEnableCondition
        OpEventGetEventEnableCondition_GetEventEnableCondition_GeneralEvtInfo: start-on-event=DemSatellite_0InternalBehavior/GetEventEnableCondition, operation=GeneralEvtInfo.GetEventEnableCondition
        OpEventGetDebouncingOfEvent_GetDebouncingOfEvent_EvtInfo_Mechanical_Fault_Unexpected_High_Current: start-on-event=DemSatellite_0InternalBehavior/GetDebouncingOfEvent, operation=EvtInfo_Mechanical_Fault_Unexpected_High_Current.GetDebouncingOfEvent
        OpEventGetDebouncingOfEvent_GetDebouncingOfEvent_EvtInfo_Electrical_Fault_Fan_Motor_Control_Circuit_Short: start-on-event=DemSatellite_0InternalBehavior/GetDebouncingOfEvent, operation=EvtInfo_Electrical_Fault_Fan_Motor_Control_Circuit_Short.GetDebouncingOfEvent
        OpEventGetDebouncingOfEvent_GetDebouncingOfEvent_EvtInfo_Mechanical_Fault_Unexpected_Low_Current: start-on-event=DemSatellite_0InternalBehavior/GetDebouncingOfEvent, operation=EvtInfo_Mechanical_Fault_Unexpected_Low_Current.GetDebouncingOfEvent
        OpEventGetDebouncingOfEvent_GetDebouncingOfEvent_EvtInfo_Electrical_Fault_Fan_Motor_Control_Circuit_Open: start-on-event=DemSatellite_0InternalBehavior/GetDebouncingOfEvent, operation=EvtInfo_Electrical_Fault_Fan_Motor_Control_Circuit_Open.GetDebouncingOfEvent
        OpEventGetDebouncingOfEvent_GetDebouncingOfEvent_GeneralEvtInfo: start-on-event=DemSatellite_0InternalBehavior/GetDebouncingOfEvent, operation=GeneralEvtInfo.GetDebouncingOfEvent
        OpEventGetMonitorStatus_GetMonitorStatus_EvtInfo_Mechanical_Fault_Unexpected_High_Current: start-on-event=DemSatellite_0InternalBehavior/GetMonitorStatus, operation=EvtInfo_Mechanical_Fault_Unexpected_High_Current.GetMonitorStatus
        OpEventGetMonitorStatus_GetMonitorStatus_EvtInfo_Electrical_Fault_Fan_Motor_Control_Circuit_Short: start-on-event=DemSatellite_0InternalBehavior/GetMonitorStatus, operation=EvtInfo_Electrical_Fault_Fan_Motor_Control_Circuit_Short.GetMonitorStatus
        OpEventGetMonitorStatus_GetMonitorStatus_EvtInfo_Mechanical_Fault_Unexpected_Low_Current: start-on-event=DemSatellite_0InternalBehavior/GetMonitorStatus, operation=EvtInfo_Mechanical_Fault_Unexpected_Low_Current.GetMonitorStatus
        OpEventGetMonitorStatus_GetMonitorStatus_EvtInfo_Electrical_Fault_Fan_Motor_Control_Circuit_Open: start-on-event=DemSatellite_0InternalBehavior/GetMonitorStatus, operation=EvtInfo_Electrical_Fault_Fan_Motor_Control_Circuit_Open.GetMonitorStatus
        OpEventGetMonitorStatus_GetMonitorStatus_GeneralEvtInfo: start-on-event=DemSatellite_0InternalBehavior/GetMonitorStatus, operation=GeneralEvtInfo.GetMonitorStatus
        OpEventSetEventStatus_SetEventStatus_Event_Mechanical_Fault_Unexpected_High_Current: start-on-event=SetEventStatus, operation=Event_Mechanical_Fault_Unexpected_High_Current.SetEventStatus
        OpEventSetEventStatus_SetEventStatus_Event_Electrical_Fault_Fan_Motor_Control_Circuit_Short: start-on-event=SetEventStatus, operation=Event_Electrical_Fault_Fan_Motor_Control_Circuit_Short.SetEventStatus
        OpEventSetEventStatus_SetEventStatus_Event_Mechanical_Fault_Unexpected_Low_Current: start-on-event=SetEventStatus, operation=Event_Mechanical_Fault_Unexpected_Low_Current.SetEventStatus
        OpEventSetEventStatus_SetEventStatus_Event_Electrical_Fault_Fan_Motor_Control_Circuit_Open: start-on-event=SetEventStatus, operation=Event_Electrical_Fault_Fan_Motor_Control_Circuit_Open.SetEventStatus
        OpEventResetEventStatus_ResetEventStatus_Event_Mechanical_Fault_Unexpected_High_Current: start-on-event=ResetEventStatus, operation=Event_Mechanical_Fault_Unexpected_High_Current.ResetEventStatus
        OpEventResetEventStatus_ResetEventStatus_Event_Electrical_Fault_Fan_Motor_Control_Circuit_Short: start-on-event=ResetEventStatus, operation=Event_Electrical_Fault_Fan_Motor_Control_Circuit_Short.ResetEventStatus
        OpEventResetEventStatus_ResetEventStatus_Event_Mechanical_Fault_Unexpected_Low_Current: start-on-event=ResetEventStatus, operation=Event_Mechanical_Fault_Unexpected_Low_Current.ResetEventStatus
        OpEventResetEventStatus_ResetEventStatus_Event_Electrical_Fault_Fan_Motor_Control_Circuit_Open: start-on-event=ResetEventStatus, operation=Event_Electrical_Fault_Fan_Motor_Control_Circuit_Open.ResetEventStatus
        OpEventResetEventDebounceStatus_ResetEventDebounceStatus_Event_Mechanical_Fault_Unexpected_High_Current: start-on-event=ResetEventDebounceStatus, operation=Event_Mechanical_Fault_Unexpected_High_Current.ResetEventDebounceStatus
        OpEventResetEventDebounceStatus_ResetEventDebounceStatus_Event_Electrical_Fault_Fan_Motor_Control_Circuit_Short: start-on-event=ResetEventDebounceStatus, operation=Event_Electrical_Fault_Fan_Motor_Control_Circuit_Short.ResetEventDebounceStatus
        OpEventResetEventDebounceStatus_ResetEventDebounceStatus_Event_Mechanical_Fault_Unexpected_Low_Current: start-on-event=ResetEventDebounceStatus, operation=Event_Mechanical_Fault_Unexpected_Low_Current.ResetEventDebounceStatus
        OpEventResetEventDebounceStatus_ResetEventDebounceStatus_Event_Electrical_Fault_Fan_Motor_Control_Circuit_Open: start-on-event=ResetEventDebounceStatus, operation=Event_Electrical_Fault_Fan_Motor_Control_Circuit_Open.ResetEventDebounceStatus
      port-api-options:
        {enable-take-address=true, indirect-api=false, port-defined-argument-value{value=3, value-type=Dem_EventIdType}, port=EvtInfo_Mechanical_Fault_Unexpected_High_Current}
        {enable-take-address=true, indirect-api=false, port-defined-argument-value{value=3, value-type=Dem_EventIdType}, port=Event_Mechanical_Fault_Unexpected_High_Current}
        {enable-take-address=true, indirect-api=false, port-defined-argument-value{value=2, value-type=Dem_EventIdType}, port=EvtInfo_Electrical_Fault_Fan_Motor_Control_Circuit_Short}
        {enable-take-address=true, indirect-api=false, port-defined-argument-value{value=2, value-type=Dem_EventIdType}, port=Event_Electrical_Fault_Fan_Motor_Control_Circuit_Short}
        {enable-take-address=true, indirect-api=false, port-defined-argument-value{value=4, value-type=Dem_EventIdType}, port=EvtInfo_Mechanical_Fault_Unexpected_Low_Current}
        {enable-take-address=true, indirect-api=false, port-defined-argument-value{value=4, value-type=Dem_EventIdType}, port=Event_Mechanical_Fault_Unexpected_Low_Current}
        {enable-take-address=true, indirect-api=false, port-defined-argument-value{value=1, value-type=Dem_EventIdType}, port=EvtInfo_Electrical_Fault_Fan_Motor_Control_Circuit_Open}
        {enable-take-address=true, indirect-api=false, port-defined-argument-value{value=1, value-type=Dem_EventIdType}, port=Event_Electrical_Fault_Fan_Motor_Control_Circuit_Open}
        enable-take-address=true, indirect-api=false, port=DemSatellite_0/GeneralEvtInfo
        enable-take-address=true, indirect-api=false, port=DemSatellite_0/CBReadData_DID_0x2_Current
      15 x runnable:
        Dem_SatelliteMainFunction
          sync call OpServerCallDem_SatelliteMainFunction_ReadData_CBReadData_DID_0x2_Current: operation=CBReadData_DID_0x2_Current.ReadData, timeout=0
        GetEventUdsStatus: can-be-invoked-concurrently=true, symbol=Dem_GetEventUdsStatus
        GetEventStatus: can-be-invoked-concurrently=true, symbol=Dem_GetEventUdsStatus
        GetEventFailed: can-be-invoked-concurrently=true, symbol=Dem_GetEventFailed
        GetEventTested: can-be-invoked-concurrently=true, symbol=Dem_GetEventTested
        GetDTCOfEvent: can-be-invoked-concurrently=true, symbol=Dem_GetDTCOfEvent
        GetFaultDetectionCounter: can-be-invoked-concurrently=true, symbol=Dem_GetFaultDetectionCounter
        GetEventFreezeFrameDataEx: can-be-invoked-concurrently=true, symbol=Dem_GetEventFreezeFrameDataEx
        GetEventExtendedDataRecordEx: can-be-invoked-concurrently=true, symbol=Dem_GetEventExtendedDataRecordEx
        GetEventEnableCondition: can-be-invoked-concurrently=true, symbol=Dem_GetEventEnableCondition
        GetDebouncingOfEvent: can-be-invoked-concurrently=true, symbol=Dem_GetDebouncingOfEvent
        GetMonitorStatus: can-be-invoked-concurrently=true, symbol=Dem_GetMonitorStatus
        SetEventStatus: can-be-invoked-concurrently=true, symbol=Dem_SetEventStatus
        ResetEventStatus: can-be-invoked-concurrently=true, symbol=Dem_ResetEventStatus
        ResetEventDebounceStatus: can-be-invoked-concurrently=true, symbol=Dem_ResetEventDebounceStatus
  swc implementation DemSatellite_0Implementation: programming-language=C, behavior=DemSatellite_0InternalBehavior
